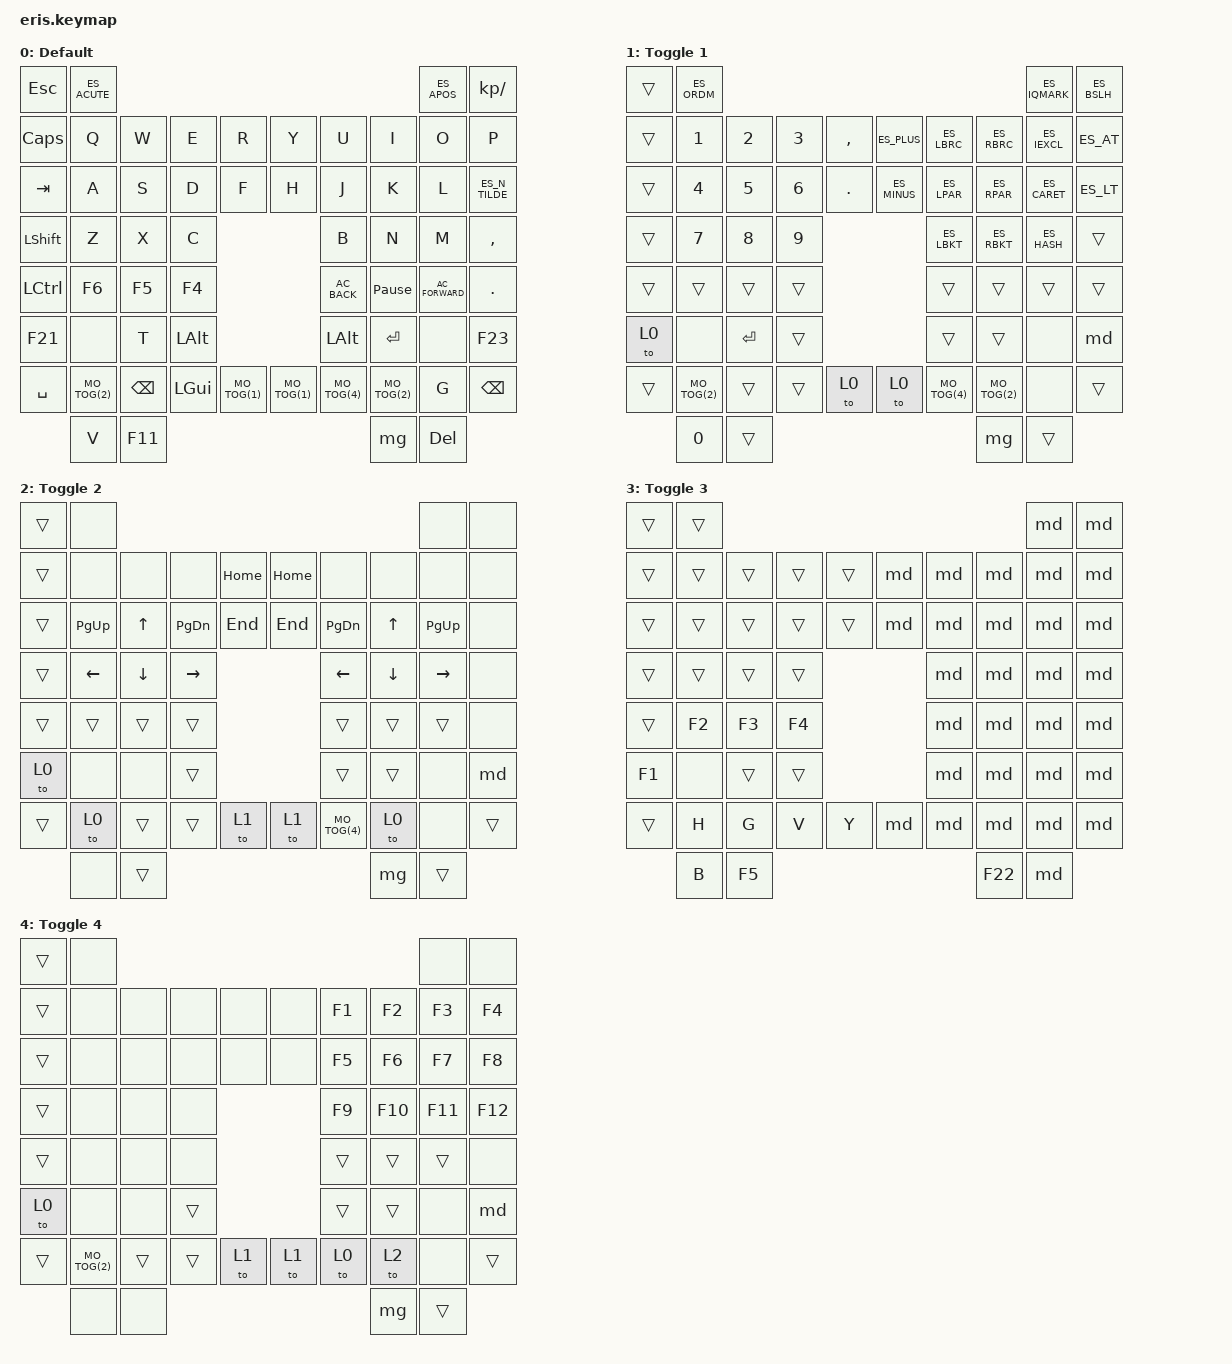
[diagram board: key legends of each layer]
/*
 * Eris BLE split keyboard — keymap (62 keys: 31 left + 31 right).
 *
 * Key position index map (use these numbers for combos.dtsi):
 *
 *    0   1                                            2   3
 *    4   5   6   7   8                    9  10  11  12  13
 *   14  15  16  17  18                   19  20  21  22  23
 *   24  25  26  27                           28  29  30  31
 *   32  33  34  35                           36  37  38  39
 *   40  41  42  43                           44  45  46  47
 *   48  49  50  51  52                   53  54  55  56  57
 *       58          59                   60          61
 *
 * Layers:
 *   0 = DEFAULT      left half preserved; right half = placeholders + controls
 *   1 = TOGGLE 1     independent toggle (also the target of the "BT mode" combo)
 *   2 = TOGGLE 2     independent toggle
 *   3 = TOGGLE 3     independent toggle
 *   4 = USB MODE     fully transparent marker layer (target of the USB combo)
 *
 * Right-half layer controls sit at the SAME physical keys on every layer,
 * so the key that turns a layer on also turns it off:
 *   pos 2  = toggle layer 1        pos 9  = toggle layer 3
 *   pos 3  = toggle layer 2        pos 10 = go to default (&to 0)
 *
 * The left half is transparent (&trans) on layers 1-4, so it always behaves
 * like the default layer. The right half is a "blank canvas": every position
 * has an editable placeholder binding — move them around as you like.
 *
 * Left-half changes forced by the new PCB matrix (nothing was dropped):
 *   old R8C3 (Z)   -> new R7C5 (pos 52)
 *   old R8C4 (F12) -> new R8C5 (pos 59)
 */

#include <behaviors.dtsi>
#include <dt-bindings/zmk/keys.h>
#include <dt-bindings/zmk/bt.h>
#include <locale/keys_es.h>
#include "combos.dtsi"
#define MO_TOG(layer) &mo_tog layer layer

/ {
    behaviors {
        mo_tog: behavior_mo_tog {
            compatible = "zmk,behavior-hold-tap";
            #binding-cells = <2>;
            flavor = "hold-preferred";
            tapping-term-ms = <200>;
            bindings = <&mo>, <&tog>;
        };
    };

    macros {
        mg: macro_game {
            compatible = "zmk,behavior-macro";
            #binding-cells = <0>;

            bindings
                = <&kp F22>
                , <&to 3>
                ;
        };

        md: macro_default {
            compatible = "zmk,behavior-macro";
            #binding-cells = <0>;

            bindings
                = <&kp F23>
                , <&to 0>
                ;
        };
    };

    keymap {
        compatible = "zmk,keymap";

        default_layer {
            display-name = "Default";
            bindings = <

&kp ESC       &kp ES_ACUTE                                                                      	     	   &kp ES_APOS       &kp KP_DIVIDE
&kp CAPSLOCK  &kp Q         &kp W         &kp E         &kp R         &kp Y         &kp U          &kp I           &kp O             &kp P
&kp TAB       &kp A         &kp S         &kp D         &kp F         &kp H         &kp J          &kp K           &kp L             &kp ES_N_TILDE
&kp LSHIFT    &kp Z         &kp X         &kp C                                     &kp B          &kp N           &kp M             &kp COMMA
&kp LCTRL     &kp F6        &kp F5        &kp F4                                    &kp C_AC_BACK  &kp PAUSE_BREAK &kp C_AC_FORWARD  &kp DOT
&kp F21       &none         &kp T         &kp LALT                                  &kp LALT       &kp ENTER       &none             &kp F23
&kp SPACE     MO_TOG(2)     &kp BSPC      &kp LGUI       MO_TOG(1)     MO_TOG(1)    MO_TOG(4)      MO_TOG(2)       &kp G             &kp BSPC
              &kp V                                      &kp F11       &mg                                         &kp DEL
            >;
        };



        toggle1_layer {
            display-name = "Toggle 1";
            bindings = <
&trans        &kp ES_ORDM                                                                             		&kp ES_IQMARK &kp ES_BSLH
&trans        &kp N1        &kp N2        &kp N3        &kp COMMA     &kp ES_PLUS   &kp ES_LBRC   &kp ES_RBRC   &kp ES_IEXCL  &kp ES_AT
&trans        &kp N4        &kp N5        &kp N6        &kp DOT       &kp ES_MINUS  &kp ES_LPAR   &kp ES_RPAR   &kp ES_CARET  &kp ES_LT
&trans        &kp N7        &kp N8        &kp N9                                    &kp ES_LBKT   &kp ES_RBKT   &kp ES_HASH   &trans
&trans        &trans        &trans        &trans                                    &trans        &trans        &trans        &trans
&to 0         &none         &kp ENTER     &trans                                    &trans        &trans        &none         &md
&trans        MO_TOG(2)     &trans        &trans        &to 0         &to 0         MO_TOG(4)     MO_TOG(2)     &none         &trans
              &kp N0                                    &trans        &mg                                       &trans
            >;
        };

        toggle2_layer {
            display-name = "Toggle 2";
            bindings = <
&trans        &none                                                                                             &none         &none 
&trans        &none         &none         &none         &kp HOME      &kp HOME      &none         &none         &none         &none  
&trans        &kp PG_UP     &kp UP        &kp PG_DN     &kp END       &kp END 	    &kp PG_DN     &kp UP        &kp PG_UP     &none   
&trans        &kp LEFT      &kp DOWN      &kp RIGHT                                 &kp LEFT      &kp DOWN      &kp RIGHT     &none   
&trans        &trans        &trans        &trans                                    &trans        &trans        &trans        &none   
&to 0         &none         &none         &trans                                    &trans        &trans        &none         &md
&trans        &to 0         &trans        &trans        &to 1         &to 1         MO_TOG(4)     &to 0         &none         &trans   
              &none                                     &trans        &mg                       		&trans 
            >;
        };

        toggle3_layer {
            display-name = "Toggle 3";
            bindings = <
&trans        &trans                                                                                            &md           &md 
&trans        &trans        &trans        &trans        &trans        &md           &md           &md           &md           &md 
&trans        &trans        &trans        &trans        &trans        &md           &md           &md           &md           &md 
&trans        &trans        &trans        &trans                                    &md           &md           &md           &md 
&trans        &kp F2        &kp F3        &kp F4                                    &md           &md           &md           &md 
&kp F1        &none         &trans        &trans                                    &md           &md           &md           &md 
&trans        &kp H         &kp G         &kp V         &kp Y         &md           &md           &md           &md           &md 
              &kp B                   			&kp F5        &kp F22            			&md   
            >;
        };

        toggle4_layer {
            display-name = "Toggle 4";
            bindings = <
&trans        &none                                                                                             &none         &none 
&trans	      &none         &none         &none         &none         &none 	    &kp F1        &kp F2        &kp F3        &kp F4   
&trans        &none         &none         &none         &none         &none         &kp F5        &kp F6        &kp F7        &kp F8   
&trans        &none         &none         &none         		            &kp F9        &kp F10       &kp F11       &kp F12   
&trans        &none         &none         &none                                     &trans        &trans        &trans        &none   
&to 0         &none         &none         &trans                                    &trans        &trans        &none         &md
&trans        MO_TOG(2)     &trans        &trans        &to 1         &to 1         &to 0         &to 2         &none         &trans   
              &none                                     &none         &mg                       		&trans  
            >;
        };
    };
};
